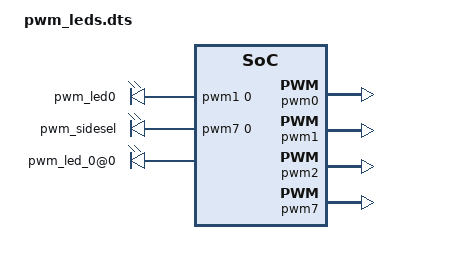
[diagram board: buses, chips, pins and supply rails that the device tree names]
/* Copyright 2021 The Chromium OS Authors. All rights reserved.
 * Use of this source code is governed by a BSD-style license that can be
 * found in the LICENSE file.
 */

/ {
	pwmleds {
		compatible = "pwm-leds";
		pwm_led0: pwm_led_0 {
			pwms = <&pwm1 0 PWM_POLARITY_INVERTED
				&pwm0 0 PWM_POLARITY_INVERTED
				&pwm2 0 PWM_POLARITY_INVERTED>;
		};
		pwm_sidesel: pwm_sidesel {
			pwms = <&pwm7 0 PWM_POLARITY_INVERTED>;
		};
	};

	cros-pwmleds {
		compatible = "cros-ec,pwm-leds";

		leds = <&pwm_led0>;
		sidesel = <&pwm_sidesel>;

		frequency = <4800>;

		color-map-red    = <100   0   0>;
		color-map-green  = <  0 100   0>;
		color-map-blue   = <  0   0 100>;
		color-map-yellow = <100  70   0>;
		color-map-white  = <100  70 100>;
		color-map-amber  = <100  20   0>;

		brightness-range = <255 255 255 0 0 0>;

		#address-cells = <1>;
		#size-cells = <0>;

		pwm_led_0@0 {
			reg = <0>;
			ec-led-name = "EC_LED_ID_POWER_LED";
		};
	};
};

/* Green LED */
&pwm0 {
	status = "okay";
	clock-bus = "NPCX_CLOCK_BUS_LFCLK";
};

/* Red LED */
&pwm1 {
	status = "okay";
	clock-bus = "NPCX_CLOCK_BUS_LFCLK";
};

/* Blue LED */
&pwm2 {
	status = "okay";
	clock-bus = "NPCX_CLOCK_BUS_LFCLK";
};

/* Side selection LED */
&pwm7 {
	status = "okay";
	clock-bus = "NPCX_CLOCK_BUS_LFCLK";
};
